# MSP430FR2433 register map
Vendor: msp430gen; File version: v0.4.0-29-g702f6f3-dirty
Registers are 16-bit, read-write, reset 0x0 unless marked. A register's access mark holds for its fields unless they carry their own. Offsets are from the block's base; [hi:lo] are bit positions; {n}, {i} and the like mark numbered series; 'fields as' and 'values as' point back to an identical list.

## TA1
Base 0x000003C0
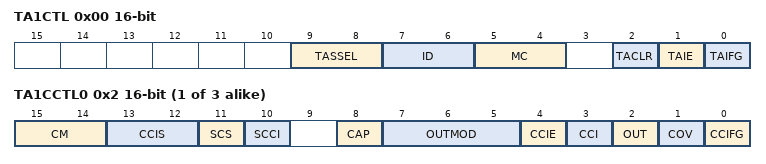
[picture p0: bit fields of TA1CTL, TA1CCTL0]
0x00 TA1CTL — Timer1_A3 Control
  [9:8] TASSEL — Timer A clock source select 1
    0=TACLK (TAxCLK); 1=ACLK; 2=SMCLK; 3=INCLK
  [7:6] ID — Timer A clock input divider 1
    0=/1; 1=/2; 2=/4; 3=/8
  [5:4] MC — Timer A mode control 1
    0=STOP (Stop mode: Timer is halted); 1=UP (Up mode: Timer counts up to TAxCCR0); 2=CONTINUOUS (Continuous mode: Timer counts up to 0FFFFh); 3=UPDOWN (Up/down mode: Timer counts up to TAxCCR0 then down to 0000h)
  [2] TACLR — Timer A counter clear
  [1] TAIE — Timer A counter interrupt enable
  [0] TAIFG — Timer A counter interrupt flag
{0x2+2i} TA1CCTL{i} (i=0..2) — Timer1_A3 Capture/Compare Control {i}
  [15:14] CM — Capture mode 1
    0=NONE (No capture); 1=RISING (Capture on rising edge); 2=FALLING (Capture on falling edge); 3=BOTH (Capture on both rising and falling edges)
  [13:12] CCIS — Capture input select 1
    0=CCIA (CCIxA); 1=CCIB (CCIxB); 2=GND; 3=VCC
  [11] SCS — Capture synchronize
  [10] SCCI — Latched capture signal (read)
  [8] CAP — Capture mode: 1 /Compare mode : 0
  [7:5] OUTMOD — Output mode 2
    0=PWM output mode: 0 - output only; 1=PWM output mode: 1 - set; 2=PWM output mode: 2 - PWM toggle/reset; 3=PWM output mode: 3 - PWM set/reset; 4=PWM output mode: 4 - toggle; 5=PWM output mode: 5 - Reset; 6=PWM output mode: 6 - PWM toggle/set; 7=PWM output mode: 7 - PWM reset/set
  [4] CCIE — Capture/compare interrupt enable
  [3] CCI — Capture input signal (read)
  [2] OUT — PWM Output signal if output mode 0
  [1] COV — Capture/compare overflow flag
  [0] CCIFG — Capture/compare interrupt flag
0x10 TA1R — Timer1_A3
{0x12+2i} TA1CCR{i} (i=0..2) — Timer1_A3 Capture/Compare {i}
0x20 TA1EX0 — Timer1_A3 Expansion Register 0
  [2:0] TAIDEX — Timer A Input divider expansion Bit: 0
    {v}=/{v+1} (Divide by {v+1}) (v=0..7)
0x2E TA1IV — Timer1_A3 Interrupt Vector Word
  [15:0] TAIV ro — Timer_A interrupt vector value
    0=NONE (No interrupt pending); 2=TACCR1 (Interrupt Source: Capture/compare 1; Interrupt Flag: TAxCCR1 CCIFG; Interrupt Priority: Highest); 4=TACCR2 (Interrupt Source: Capture/compare 2; Interrupt Flag: TAxCCR2 CCIFG); 6=TACCR3 (Interrupt Source: Capture/compare 3; Interrupt Flag: TAxCCR3 CCIFG); 8=TACCR4 (Interrupt Source: Capture/compare 4; Interrupt Flag: TAxCCR4 CCIFG); 10=TACCR5 (Interrupt Source: Capture/compare 5; Interrupt Flag: TAxCCR5 CCIFG); 12=TACCR6 (Interrupt Source: Capture/compare 6; Interrupt Flag: TAxCCR6 CCIFG); 14=TAIFG (Interrupt Source: Timer overflow; Interrupt Flag: TAxCTL TAIFG; Interrupt Priority: Lowest)

## TA2
Base 0x00000400
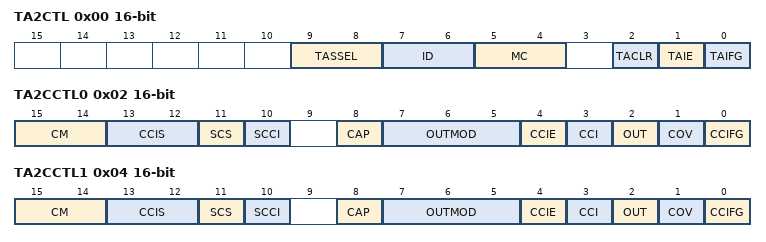
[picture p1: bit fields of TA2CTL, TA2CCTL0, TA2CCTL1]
0x00 TA2CTL — Timer2_A2 Control
  [9:8] TASSEL — Timer A clock source select 1
    0=TACLK (TAxCLK); 1=ACLK; 2=SMCLK; 3=INCLK
  [7:6] ID — Timer A clock input divider 1
    0=/1; 1=/2; 2=/4; 3=/8
  [5:4] MC — Timer A mode control 1
    0=STOP (Stop mode: Timer is halted); 1=UP (Up mode: Timer counts up to TAxCCR0); 2=CONTINUOUS (Continuous mode: Timer counts up to 0FFFFh); 3=UPDOWN (Up/down mode: Timer counts up to TAxCCR0 then down to 0000h)
  [2] TACLR — Timer A counter clear
  [1] TAIE — Timer A counter interrupt enable
  [0] TAIFG — Timer A counter interrupt flag
0x02 TA2CCTL0 — Timer2_A2 Capture/Compare Control 0
  [15:14] CM — Capture mode 1
    0=NONE (No capture); 1=RISING (Capture on rising edge); 2=FALLING (Capture on falling edge); 3=BOTH (Capture on both rising and falling edges)
  [13:12] CCIS — Capture input select 1
    0=CCIA (CCIxA); 1=CCIB (CCIxB); 2=GND; 3=VCC
  [11] SCS — Capture synchronize
  [10] SCCI — Latched capture signal (read)
  [8] CAP — Capture mode: 1 /Compare mode : 0
  [7:5] OUTMOD — Output mode 2
    0=PWM output mode: 0 - output only; 1=PWM output mode: 1 - set; 2=PWM output mode: 2 - PWM toggle/reset; 3=PWM output mode: 3 - PWM set/reset; 4=PWM output mode: 4 - toggle; 5=PWM output mode: 5 - Reset; 6=PWM output mode: 6 - PWM toggle/set; 7=PWM output mode: 7 - PWM reset/set
  [4] CCIE — Capture/compare interrupt enable
  [3] CCI — Capture input signal (read)
  [2] OUT — PWM Output signal if output mode 0
  [1] COV — Capture/compare overflow flag
  [0] CCIFG — Capture/compare interrupt flag
0x04 TA2CCTL1 — Timer2_A2 Capture/Compare Control 1
  fields as TA2CCTL0
0x10 TA2R — Timer2_A2
0x12 TA2CCR0 — Timer2_A2 Capture/Compare 0
0x14 TA2CCR1 — Timer2_A2 Capture/Compare 1
0x20 TA2EX0 — Timer2_A2 Expansion Register 0
  [2:0] TAIDEX — Timer A Input divider expansion Bit: 0
    {v}=/{v+1} (Divide by {v+1}) (v=0..7)
0x2E TA2IV — Timer2_A2 Interrupt Vector Word
  [15:0] TAIV ro — Timer_A interrupt vector value
    0=NONE (No interrupt pending); 2=TACCR1 (Interrupt Source: Capture/compare 1; Interrupt Flag: TAxCCR1 CCIFG; Interrupt Priority: Highest); 4=TACCR2 (Interrupt Source: Capture/compare 2; Interrupt Flag: TAxCCR2 CCIFG); 6=TACCR3 (Interrupt Source: Capture/compare 3; Interrupt Flag: TAxCCR3 CCIFG); 8=TACCR4 (Interrupt Source: Capture/compare 4; Interrupt Flag: TAxCCR4 CCIFG); 10=TACCR5 (Interrupt Source: Capture/compare 5; Interrupt Flag: TAxCCR5 CCIFG); 12=TACCR6 (Interrupt Source: Capture/compare 6; Interrupt Flag: TAxCCR6 CCIFG); 14=TAIFG (Interrupt Source: Timer overflow; Interrupt Flag: TAxCTL TAIFG; Interrupt Priority: Lowest)
